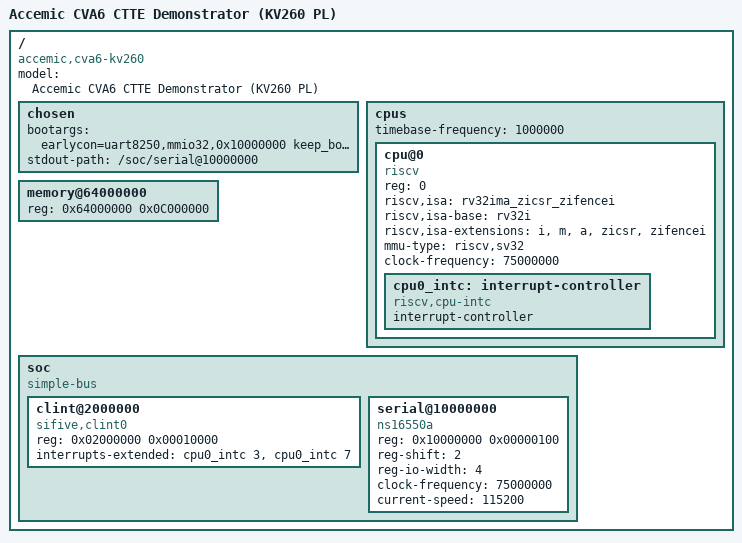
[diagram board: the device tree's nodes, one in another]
/dts-v1/;

/*
 * SPDX-FileCopyrightText: 2026 Accemic Technologies GmbH
 * SPDX-License-Identifier: ISC
 *
 * cva6_kv260.dts -- devicetree of the CVA6 Linux machine in the KV260's PL.
 *
 * Describes EXACTLY what cva6_linux_soc_top implements -- nothing more:
 *   1 hart (rv32ima_zicsr_zifencei, Sv32), CLINT @0x0200_0000,
 *   8250 console @0x1000_0000 (reg-shift 2, 32 bit), RAM @0x6400_0000 +192 MiB.
 *
 * Deliberately NOT included:
 *   - PLIC. There is none. The console is pure polling (the peripheral
 *     reports THRE/TEMT permanently, the PS reads out the ring). The serial
 *     node therefore also carries no "interrupts" property.
 *   - Anything with F/D/C. The toolchain builds rv32ima without
 *     compression; a wrong isa string here would not fix that, only hide it.
 *
 * The console runs via earlycon (uart8250,mmio32) instead of the regular
 * 8250 driver: earlycon writes directly into THR and polls LSR bit 5 --
 * exactly the feature set our peripheral has. The regular driver would run
 * an 8250 autoconfiguration (loopback via MCR, FIFO detection via FCR/IIR)
 * that our minimal peripheral does not serve. keep_bootcon keeps earlycon
 * active in case no regular port gets registered -- otherwise the boot
 * would go silent exactly when it gets interesting.
 */

/ {
	#address-cells = <1>;
	#size-cells = <1>;
	compatible = "accemic,cva6-kv260";
	model = "Accemic CVA6 CTTE Demonstrator (KV260 PL)";

	chosen {
		bootargs = "earlycon=uart8250,mmio32,0x10000000 keep_bootcon console=ttyS0 rdinit=/sbin/init";
		stdout-path = "/soc/serial@10000000";
	};

	cpus {
		#address-cells = <1>;
		#size-cells = <0>;
		/* CLINT clock: cva6_linux_soc_top divides CLK_HZ down to TICK_HZ = 1 MHz */
		timebase-frequency = <1000000>;

		/* reg == mhartid. The single-core SoC sets HART_ID=0 in
		 * cva6_soc_synth_wrap. This is not a cosmetic detail: with the
		 * hart ID 2 inherited from a three-core bring-up, OpenSBI only
		 * ever jumped into _start_hang (wfi, no console character at
		 * all), and even with a matching reg=<2> it then failed at
		 * sbi_hsm_hart_start_finish ("hart is in invalid state"). Both
		 * diagnosed on the board -- the first finding came EXCLUSIVELY
		 * from the C-Trace capture, because the console stayed silent
		 * (2026-07-27). */
		cpu@0 {
			device_type = "cpu";
			reg = <0>;
			status = "okay";
			compatible = "riscv";
			riscv,isa = "rv32ima_zicsr_zifencei";
			riscv,isa-base = "rv32i";
			riscv,isa-extensions = "i", "m", "a", "zicsr", "zifencei";
			mmu-type = "riscv,sv32";
			clock-frequency = <75000000>;

			cpu0_intc: interrupt-controller {
				#interrupt-cells = <1>;
				compatible = "riscv,cpu-intc";
				interrupt-controller;
			};
		};
	};

	memory@64000000 {
		device_type = "memory";
		/* 0x6400_0000 + 192 MiB -- second half of the reserved PL window
		 * v3; the first 64 MiB starting at 0x6000_0000 belong to the
		 * trace sink. */
		reg = <0x64000000 0x0C000000>;
	};

	soc {
		#address-cells = <1>;
		#size-cells = <1>;
		compatible = "simple-bus";
		ranges;

		clint@2000000 {
			compatible = "sifive,clint0", "riscv,clint0";
			reg = <0x02000000 0x00010000>;
			interrupts-extended = <&cpu0_intc 3>, <&cpu0_intc 7>;
		};

		serial@10000000 {
			compatible = "ns16550a";
			reg = <0x10000000 0x00000100>;
			reg-shift = <2>;
			reg-io-width = <4>;
			clock-frequency = <75000000>;
			current-speed = <115200>;
			/* no "interrupts": there is no interrupt controller */
		};
	};
};
